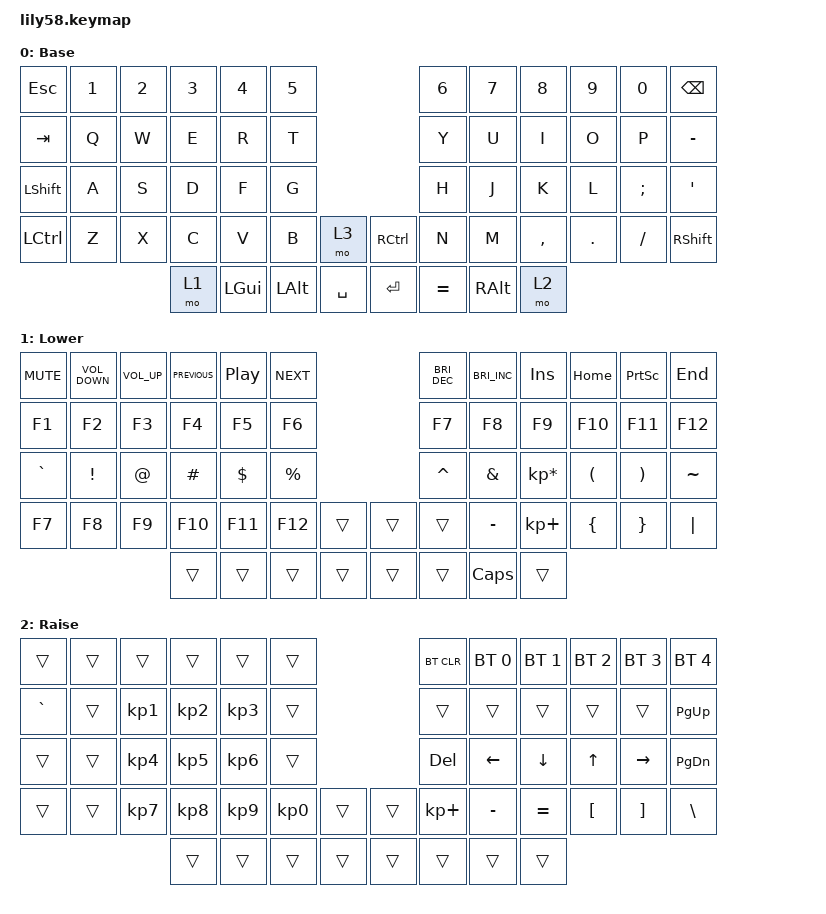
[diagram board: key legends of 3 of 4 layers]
/*
 * Copyright (c) 2020 The ZMK Contributors
 *
 * SPDX-License-Identifier: MIT
 */

#include <behaviors.dtsi>
#include <dt-bindings/zmk/bt.h>
#include <dt-bindings/zmk/keys.h>

/ {
    keymap {
        compatible = "zmk,keymap";

        default_layer {
            // ------------------------------------------------------------------------------------------------------------
            // |  ESC  |  1  |  2  |  3    |  4   |  5   |                  |  6   |  7    |  8    |  9   |   0   | BACKSPACE  |
            // |  TAB  |  Q  |  W  |  E    |  R   |  T   |                  |  Y   |  U    |  I    |  O   |   P   |     -      |
            // | SHIFT |  A  |  S  |  D    |  F   |  G   |                  |  H   |  J    |  K    |  L   |   ;   |     '      |
            // |  CTRL |  Z  |  X  |  C    |  V   |  B   |  FN   |  | RCTRL |  N   |  M    |  ,    |  .   |   /   |   SHIFT    |
            //                     | LOWER | GUI  |  ALT | SPACE |  | ENTER |  =   | ALTGR | RAISE |

            display-name = "Base";
            bindings = <
&kp ESC    &kp N1  &kp N2  &kp N3  &kp N4    &kp N5                                        &kp N6     &kp N7        &kp N8     &kp N9   &kp N0    &kp BACKSPACE
&kp TAB    &kp Q   &kp W   &kp E   &kp R     &kp T                                         &kp Y      &kp U         &kp I      &kp O    &kp P     &kp MINUS
&kp LSHFT  &kp A   &kp S   &kp D   &kp F     &kp G                                         &kp H      &kp J         &kp K      &kp L    &kp SEMI  &kp SQT
&kp LCTRL  &kp Z   &kp X   &kp C   &kp V     &kp B         &mo 3        &kp RIGHT_CONTROL  &kp N      &kp M         &kp COMMA  &kp DOT  &kp FSLH  &kp RSHFT
                           &mo 1   &kp LGUI  &kp LEFT_ALT  &kp SPACE    &kp RET            &kp EQUAL  &kp RIGHT_ALT  &mo 2
            >;

            sensor-bindings = <&inc_dec_kp C_VOL_UP C_VOL_DN>;
        };

        lower_layer {
            // --------------------------------------------------------------------------------------------------------------
            // | MUTE  | VOL- | VOL+ | PREV | PLAY | NEXT |                   | BRT- |   BRT+   | INS   | HOME | PSCRN |  END  |
            // |  F1   |  F2  |  F3  |  F4  |  F5  |  F6  |                   |  F7  |    F8    |  F9   |  F10 |  F11  |  F12  |
            // |   `   |  !   |  @   |  #   |  $   |  %   |                   |  ^   |    &     |  *    |  (   |   )   |   ~   |
            // |  F7   |  F8  |  F9  |  F10 |  F11 |  F12 |        |  |       |      |     _    |  +    |  {   |   }   |  "|"  |
            //                       |      |      |      |        |  |       |      | CAPSLOCK |       |

            display-name = "Lower";
            bindings = <
&kp C_MUTE         &kp C_VOLUME_DOWN  &kp C_VOLUME_UP  &kp C_PREVIOUS  &kp C_PLAY_PAUSE  &kp C_NEXT                    &kp C_BRIGHTNESS_DEC  &kp C_BRIGHTNESS_INC  &kp INSERT       &kp HOME  &kp PRINTSCREEN  &kp END
&kp F1             &kp F2             &kp F3           &kp F4          &kp F5            &kp F6                        &kp F7                &kp F8                &kp F9           &kp F10   &kp F11          &kp F12
&kp GRAVE          &kp EXCL           &kp AT           &kp HASH        &kp DOLLAR        &kp PRCNT                     &kp CARET             &kp AMPS              &kp KP_MULTIPLY  &kp LPAR  &kp RPAR         &kp TILDE
&kp F7             &kp F8             &kp F9           &kp F10         &kp F11           &kp F12     &trans    &trans  &trans                &kp MINUS             &kp KP_PLUS      &kp LBRC  &kp RBRC         &kp PIPE
                                                       &trans          &trans            &trans      &trans    &trans  &trans                &kp CAPSLOCK          &trans
            >;

            sensor-bindings = <&inc_dec_kp C_VOL_UP C_VOL_DN>;
        };

        raise_layer {
            // -------------------------------------------------------------------------------------------------------
            // |       |     |     |     |     |     |                   | BTCLR |  BT0  |  BT1  | BT2 |  BT3 | BT4  |
            // |   `   |     |  1  |  2  |  3  |     |                   |       |       |       |     |      | PGUP |
            // |       |     |  4  |  5  |  6  |     |                   | DEL   |   <-  |   v   |  ^  |  ->  | PGDN |
            // |       |     |  7  |  8  |  9  |  0  |        |  |       |  +    |   -   |   =   |  [  |   ]  |   \  |
            //                     |     |     |     |        |  |       |       |       |       |

            display-name = "Raise";
            bindings = <
&trans     &trans  &trans           &trans           &trans           &trans                             &bt BT_CLR   &bt BT_SEL 0  &bt BT_SEL 1  &bt BT_SEL 2  &bt BT_SEL 3  &bt BT_SEL 4
&kp GRAVE  &trans  &kp KP_NUMBER_1  &kp KP_NUMBER_2  &kp KP_NUMBER_3  &trans                             &trans       &trans        &trans        &trans        &trans        &kp PG_UP
&trans     &trans  &kp KP_NUMBER_4  &kp KP_NUMBER_5  &kp KP_NUMBER_6  &trans                             &kp DELETE   &kp LEFT      &kp DOWN      &kp UP        &kp RIGHT     &kp PAGE_DOWN
&trans     &trans  &kp KP_NUMBER_7  &kp KP_NUMBER_8  &kp KP_NUMBER_9  &kp KP_NUMBER_0  &trans    &trans  &kp KP_PLUS  &kp MINUS     &kp EQUAL     &kp LBKT      &kp RBKT      &kp BSLH
                                    &trans           &trans           &trans           &trans    &trans  &trans       &trans        &trans
            >;

            sensor-bindings = <&inc_dec_kp C_VOL_UP C_VOL_DN>;
        };

        fn_layer {
            // ------------------------------------------------------------------------------------------------------------------
            // |  BACKSPACE |  N0  |  N9  |   N8  |   N7  |   N6  |                   |       |       |       |       |       |       |
            // |      -     |  P   |   O  |   I   |   U   |   Y   |                   |       |       |       |       |       |       |
            // |      '     |  ;   |   L  |   K   |   J   |   H   |                   |       |       |       |       |       |       |
            // |    SHIFT   |  /   |   .  |   ,   |   M   |   N   |        |  |       |       |       |       |       |       |       |
            //                            |       |       |       | ENTER  |  |       |       |       |
            display-name = "Fn";
            bindings = <
&kp BACKSPACE  &kp N0    &kp N9   &kp N8     &kp N7  &kp N6                      &trans  &trans  &trans  &trans  &trans  &trans
&kp MINUS      &kp P     &kp O    &kp I      &kp U   &kp Y                       &trans  &trans  &trans  &trans  &trans  &trans
&kp SQT        &kp SEMI  &kp L    &kp K      &kp J   &kp H                       &trans  &trans  &trans  &trans  &trans  &trans
&kp RSHFT      &kp FSLH  &kp DOT  &kp COMMA  &kp M   &kp N               &trans  &trans  &trans  &trans  &trans  &trans  &trans
                                  &trans     &trans  &trans  &kp RET     &trans  &trans  &trans  &trans
            >;

            sensor-bindings = <&inc_dec_kp C_VOL_UP C_VOL_DN>;
        };
    };
};
